# STM32F0x0 register map
File version: 1.2
CPU: CM0 r0p0, little endian, no MPU, no FPU, 3 interrupt priority bits
Registers are 32-bit, read-write, reset 0x0 unless marked. A register's access mark holds for its fields unless they carry their own. Offsets are from the block's base; [hi:lo] are bit positions; {n}, {i} and the like mark numbered series; 'fields as' and 'values as' point back to an identical list.

## DMA1 — DMA controller
Base 0x40020000
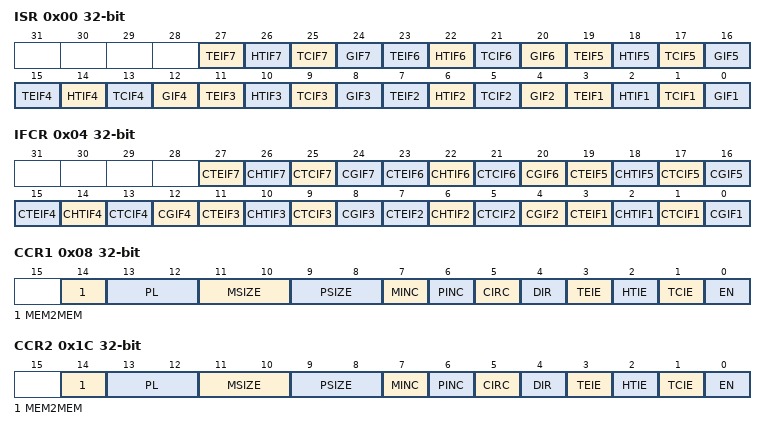
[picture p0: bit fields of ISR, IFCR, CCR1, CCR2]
0x00 ISR ro — DMA interrupt status register (DMA_ISR)
  [4n-1] TEIF{n} (n=1..7) — Channel {n} Transfer Error flag
  [4n-2] HTIF{n} (n=1..7) — Channel {n} Half Transfer Complete flag
  [4n-3] TCIF{n} (n=1..7) — Channel {n} Transfer Complete flag
  [4n-4] GIF{n} (n=1..7) — Channel {n} Global interrupt flag
0x04 IFCR wo — DMA interrupt flag clear register (DMA_IFCR)
  [4n-1] CTEIF{n} (n=1..7) — Channel {n} Transfer Error clear
  [4n-2] CHTIF{n} (n=1..7) — Channel {n} Half Transfer clear
  [4n-3] CTCIF{n} (n=1..7) — Channel {n} Transfer Complete clear
  [4n-4] CGIF{n} (n=1..7) — Channel {n} Global interrupt clear
0x08 CCR1 — DMA channel configuration register (DMA_CCR)
  [14] MEM2MEM — Memory to memory mode
  [13:12] PL — Channel Priority level
  [11:10] MSIZE — Memory size
  [9:8] PSIZE — Peripheral size
  [7] MINC — Memory increment mode
  [6] PINC — Peripheral increment mode
  [5] CIRC — Circular mode
  [4] DIR — Data transfer direction
  [3] TEIE — Transfer error interrupt enable
  [2] HTIE — Half Transfer interrupt enable
  [1] TCIE — Transfer complete interrupt enable
  [0] EN — Channel enable
0x0C CNDTR1 — DMA channel 1 number of data register
  [15:0] NDT — Number of data to transfer
0x10 CPAR1 — DMA channel 1 peripheral address register
  [31:0] PA — Peripheral address
{0x0+0x14*i} CMAR{i} (i=1..7) — DMA channel {i} memory address register
  [31:0] MA — Memory address
0x1C CCR2 — DMA channel configuration register (DMA_CCR)
  fields as CCR1
0x20 CNDTR2 — DMA channel 2 number of data register
  [15:0] NDT — Number of data to transfer
0x24 CPAR2 — DMA channel 2 peripheral address register
  [31:0] PA — Peripheral address
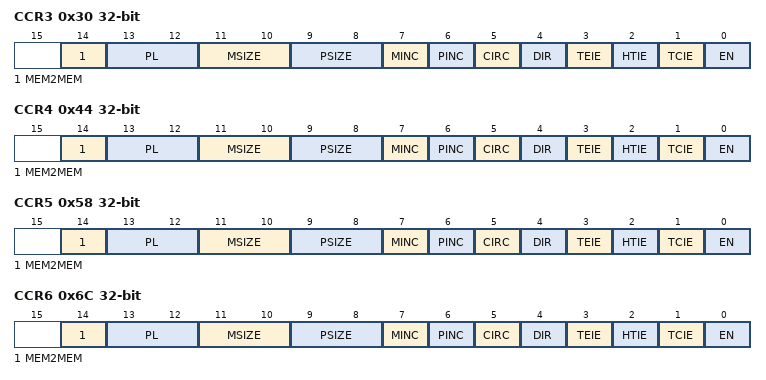
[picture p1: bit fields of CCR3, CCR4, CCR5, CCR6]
0x30 CCR3 — DMA channel configuration register (DMA_CCR)
  fields as CCR1
0x34 CNDTR3 — DMA channel 3 number of data register
  [15:0] NDT — Number of data to transfer
0x38 CPAR3 — DMA channel 3 peripheral address register
  [31:0] PA — Peripheral address
0x44 CCR4 — DMA channel configuration register (DMA_CCR)
  fields as CCR1
0x48 CNDTR4 — DMA channel 4 number of data register
  [15:0] NDT — Number of data to transfer
0x4C CPAR4 — DMA channel 4 peripheral address register
  [31:0] PA — Peripheral address
0x58 CCR5 — DMA channel configuration register (DMA_CCR)
  fields as CCR1
0x5C CNDTR5 — DMA channel 5 number of data register
  [15:0] NDT — Number of data to transfer
0x60 CPAR5 — DMA channel 5 peripheral address register
  [31:0] PA — Peripheral address
0x6C CCR6 — DMA channel configuration register (DMA_CCR)
  fields as CCR1
0x70 CNDTR6 — DMA channel 6 number of data register
  [15:0] NDT — Number of data to transfer
0x74 CPAR6 — DMA channel 6 peripheral address register
  [31:0] PA — Peripheral address
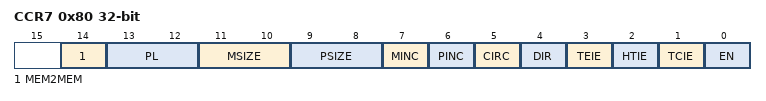
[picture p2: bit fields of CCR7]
0x80 CCR7 — DMA channel configuration register (DMA_CCR)
  fields as CCR1
0x84 CNDTR7 — DMA channel 7 number of data register
  [15:0] NDT — Number of data to transfer
0x88 CPAR7 — DMA channel 7 peripheral address register
  [31:0] PA — Peripheral address

## SYSCFG — System configuration controller
Base 0x40010000
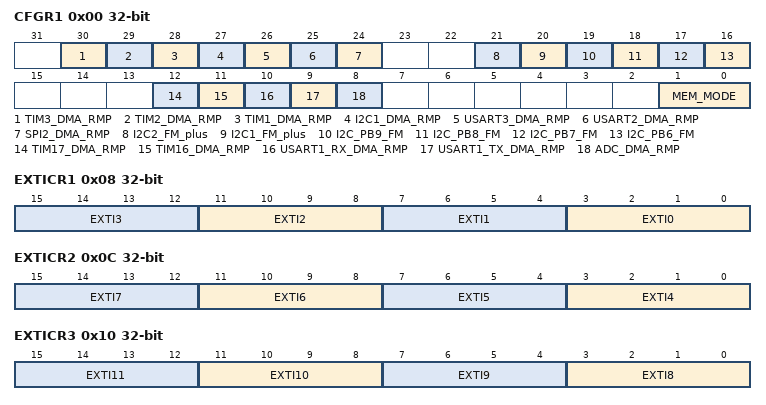
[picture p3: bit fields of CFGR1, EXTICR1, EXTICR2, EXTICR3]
0x00 CFGR1 — configuration register 1
  [30] TIM3_DMA_RMP — TIM3 DMA request remapping bit
  [29] TIM2_DMA_RMP — TIM2 DMA request remapping bit
  [28] TIM1_DMA_RMP — TIM1 DMA request remapping bit
  [27] I2C1_DMA_RMP — I2C1 DMA request remapping bit
  [26] USART3_DMA_RMP — USART3 DMA request remapping bit
  [25] USART2_DMA_RMP — USART2 DMA request remapping bit
  [24] SPI2_DMA_RMP — SPI2 DMA request remapping bit
  [21] I2C2_FM_plus — FM+ driving capability activation for I2C2
  [20] I2C1_FM_plus — FM+ driving capability activation for I2C1
  [19] I2C_PB9_FM — Fast Mode Plus (FM+) driving capability activation bits.
  [18] I2C_PB8_FM — Fast Mode Plus (FM+) driving capability activation bits.
  [17] I2C_PB7_FM — Fast Mode Plus (FM+) driving capability activation bits.
  [16] I2C_PB6_FM — Fast Mode Plus (FM plus) driving capability activation bits.
  [12] TIM17_DMA_RMP — TIM17 DMA request remapping bit
  [11] TIM16_DMA_RMP — TIM16 DMA request remapping bit
  [10] USART1_RX_DMA_RMP — USART1_RX DMA request remapping bit
  [9] USART1_TX_DMA_RMP — USART1_TX DMA remapping bit
  [8] ADC_DMA_RMP — ADC DMA remapping bit
  [1:0] MEM_MODE — Memory mapping selection bits
0x08 EXTICR1 — external interrupt configuration register 1
  [4n+3:4n] EXTI{n} (n=0..3) — EXTI {n} configuration bits
0x0C EXTICR2 — external interrupt configuration register 2
  [4n-13:4n-16] EXTI{n} (n=4..7) — EXTI {n} configuration bits
0x10 EXTICR3 — external interrupt configuration register 3
  [4n-29:4n-32] EXTI{n} (n=8..11) — EXTI {n} configuration bits
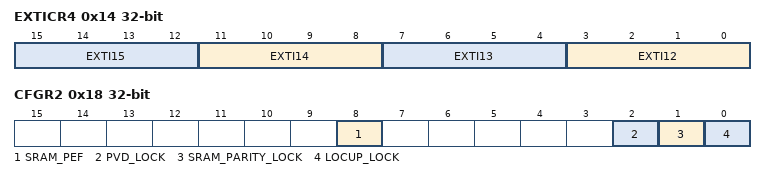
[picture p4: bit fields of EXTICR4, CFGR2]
0x14 EXTICR4 — external interrupt configuration register 4
  [4n-45:4n-48] EXTI{n} (n=12..15) — EXTI {n} configuration bits
0x18 CFGR2 — configuration register 2
  [8] SRAM_PEF — SRAM parity flag
  [2] PVD_LOCK — PVD lock enable bit
  [1] SRAM_PARITY_LOCK — SRAM parity lock bit
  [0] LOCUP_LOCK — Cortex-M0 LOCKUP bit enable bit
